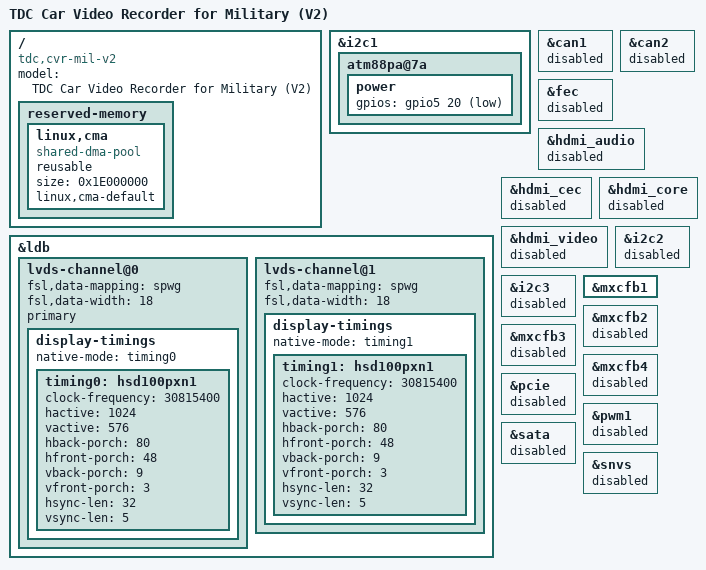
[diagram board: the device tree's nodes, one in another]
/*
 * Technology Development Co.,Ltd
 * http://www.nedi.com.cn
 * Varphone Wong <varphone@qq.com>
 */

/dts-v1/;
#include "imx6q.dtsi"
#include "myimx6ek200-cm.dtsi"

/ {
	model = "TDC Car Video Recorder for Military (V2)";
	compatible = "tdc,cvr-mil-v2", "myzr,myimx6", "myzr,myimx6q", "myzr,myimx6cb200", "myzr,myimx6ek200", "fsl,imx6q", "fsl,imx6q-ldb";

	reserved-memory {
		#address-cells = <1>;
		#size-cells = <1>;
		ranges;

		/* global autoconfigured region for contiguous allocations */
		linux,cma {
			compatible = "shared-dma-pool";
			reusable;
			size = <0x1E000000>;
			linux,cma-default;
		};
	};
};

&i2c1 {

	atm88pa@7a {
		power {
			/* poweroff GPIO5_IO20, ACTIVE_LOW */
			gpios = <&gpio5 20 1>;
		};
	};
};

&ldb {
	status = "okay";

	lvds-channel@0 {
		fsl,data-mapping = "spwg";
		fsl,data-width = <18>;
		primary;
		status = "okay";

		display-timings {
			native-mode = <&timing0>;
			timing0: hsd100pxn1 {
				clock-frequency = <30815400>;/* clock-frequency = <46815400>; */
				hactive = <1024>;
				vactive = <576>;
				hback-porch = <80>;
				hfront-porch = <48>;
				vback-porch = <9>;
				vfront-porch = <3>;
				hsync-len = <32>;
				vsync-len = <5>;
			};
		};
	};

	lvds-channel@1 {
		fsl,data-mapping = "spwg";
		fsl,data-width = <18>;
		status = "okay";

		display-timings {
			native-mode = <&timing1>;
			timing1: hsd100pxn1 {
				clock-frequency = <30815400>;/* clock-frequency = <46815400>; */
				hactive = <1024>;
				vactive = <576>;
				hback-porch = <80>;
				hfront-porch = <48>;
				vback-porch = <9>;
				vfront-porch = <3>;
				hsync-len = <32>;
				vsync-len = <5>;
			};
		};
	};
};

&can1 {
	status = "disabled";
};

&can2 {
	status = "disabled";
};

&fec {
	status = "disabled";
};

&hdmi_audio {
	status = "disabled";
};

&hdmi_cec {
	status = "disabled";
};

&hdmi_core {
	status = "disabled";
};

&hdmi_video {
	status = "disabled";
};

&i2c2 {
	status = "disabled";
};

&i2c3 {
	status = "disabled";
};

&mxcfb1 {
	status = "okay";
};

&mxcfb2 {
	status = "disabled";
};

&mxcfb3 {
	status = "disabled";
};

&mxcfb4 {
	status = "disabled";
};

&pcie {
	status = "disabled";
};

&pwm1 {
	status = "disabled";
};

&sata {
	status = "disabled";
};

&snvs {
	status = "disabled";
};
